AUTOSAR XML (schema 00044)
package /ComponentTypes
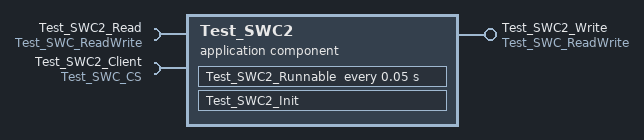
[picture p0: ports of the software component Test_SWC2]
  application sw component type Test_SWC2
    provide port Test_SWC2_Write: nonqueued-sender-com-spec{data-element=u8_Signal, init-value=0}, provided-interface=Test_SWC_ReadWrite
    require port Test_SWC2_Read: nonqueued-receiver-com-spec{data-element=u8_Signal, init-value=0}, required-interface=Test_SWC_ReadWrite
    require port Test_SWC2_Client: client-com-spec=Operation, required-interface=Test_SWC_CS
    behavior Test_SWC2_InternalBehavior
      timing event TMT_Runnable: start-on-event=Test_SWC2_Runnable, period=0.05
      init event Test_SWC2_InitEvent: start-on-event=Test_SWC2_Init
      runnable Test_SWC2_Runnable: minimum-start-interval=0.05
        data-receive-point-by-arguments:
          access REC_Test_SWC2_Read_u8_Signal: accessed-variable=Test_SWC2_Read.u8_Signal
        data-send-points:
          access SEND_Test_SWC2_Write_u8_Signal: accessed-variable=Test_SWC2_Write.u8_Signal
        sync call SC_Test_SWC_Client_Operation: operation=Test_SWC2_Client.Operation
      runnable Test_SWC2_Init
  swc implementation Test_SWC2_Implementation: behavior=Test_SWC2_InternalBehavior
